# dbb_ctrl register map
Registers are 16-bit, access not given, no defined reset value unless marked. A register's access mark holds for its fields unless they carry their own. Offsets are from the block's base; lines under a group give offsets from that group; [hi:lo] are bit positions; {n}, {i} and the like mark numbered series; 'fields as' and 'values as' point back to an identical list; <NAME> marks a mode.

## Memory map
? dbb_ctrl — DIBS Control Config

## dbb_ctrl — DIBS Control Config
Base ?
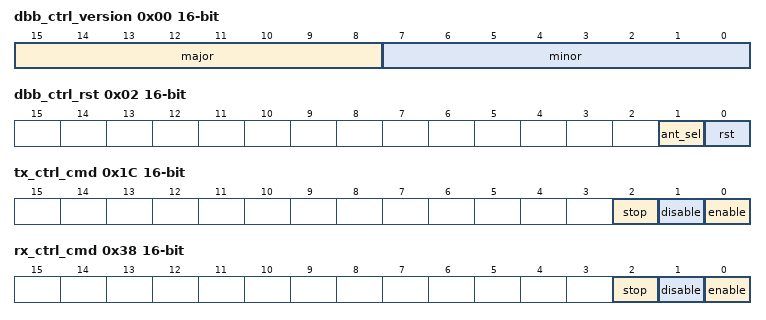
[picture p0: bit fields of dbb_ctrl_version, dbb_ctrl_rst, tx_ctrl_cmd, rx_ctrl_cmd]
0x00 dbb_ctrl_version — version
  [15:8] major — version register major
  [7:0] minor — Version register minor
0x02 dbb_ctrl_rst — Digital baseband reset
  [1] ant_sel
  [0] rst — reset
0x04 tx_ctrl_dbb_en_dly — When a transmit needs to start automatically after Tifs
{0x8+4i} tx_ctrl_rffe_en_dly[{i}] (i=0..1) — RFE enable dly [1]: the delay between the start of the SPI sequencer or the POWER on. RFE enable delay [2]: the delay between the start of the second burst and the POWER on. (if the RFE enable delay [2] = 0 there is no second burst)
0x10 tx_ctrl_dbb_dis_dly — the delay for disabling the DBB
{0x14+4i} tx_ctrl_rffe_dis_dly[{i}] (i=0..1) — RFE disable dly [1]: the delay between the start of the SPI sequencer or the POWER on. RFE disable delay [2]: the delay between the start of the second burst and the POWER on. (if the RFE disable delay [2] = 0 there is no second burst)
0x1C tx_ctrl_cmd — cmd
  [2] stop — Stops the automatic timing for TIFS
  [1] disable — Direct register control disable of TX transmission
  [0] enable — Direct register control enable of TX transmission
0x1E tx_ctrl_debug_en_tx_on_sfd_to — Besides RX received also enable TX on SFD timeout (used for debugging only)
0x20 rx_ctrl_dbb_en_dly — When a transmit needs to start automatically after Tifs
{0x24+4i} rx_ctrl_rffe_en_dly[{i}] (i=0..1) — RFE enable dly [1]: the delay between the start of the SPI sequencer or the POWER on. RFE enable delay [2]: the delay between the start of the second burst and the POWER on. (if the RFE enable delay [2] = 0 there is no second burst)
0x2C rx_ctrl_dbb_dis_dly — the delay for disabling the DBB
{0x30+4i} rx_ctrl_rffe_dis_dly[{i}] (i=0..1) — RFE disable dly [1]: the delay between the start of the SPI sequencer or the POWER on. RFE disable delay [2]: the delay between the start of the second burst and the POWER on. (if the RFE disable delay [2] = 0 there is no second burst)
0x38 rx_ctrl_cmd — cmd
  [2] stop — Stops the automatic timing for TIFS
  [1] disable — Direct register control disable of RX transmission
  [0] enable — Direct register control enable of RX transmission
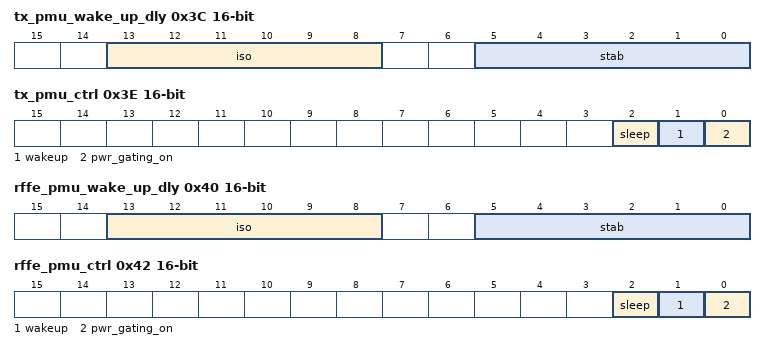
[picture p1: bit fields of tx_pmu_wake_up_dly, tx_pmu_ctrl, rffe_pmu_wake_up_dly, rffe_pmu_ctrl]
0x3C tx_pmu_wake_up_dly — wake_up_dly
  [13:8] iso — The delay between turning off the isolation and signalling that the power is on
  [5:0] stab — The delay between the wake up event and turning off the isolation
0x3E tx_pmu_ctrl — ctrl
  [2] sleep — Register controlled sleep
  [1] wakeup — Register controlled wakeup
  [0] pwr_gating_on — Actually do power gating, if off the power on signal is still toggled and is used to start the actual TX or RX
0x40 rffe_pmu_wake_up_dly — wake_up_dly
  fields as tx_pmu_wake_up_dly
0x42 rffe_pmu_ctrl — ctrl
  fields as tx_pmu_ctrl
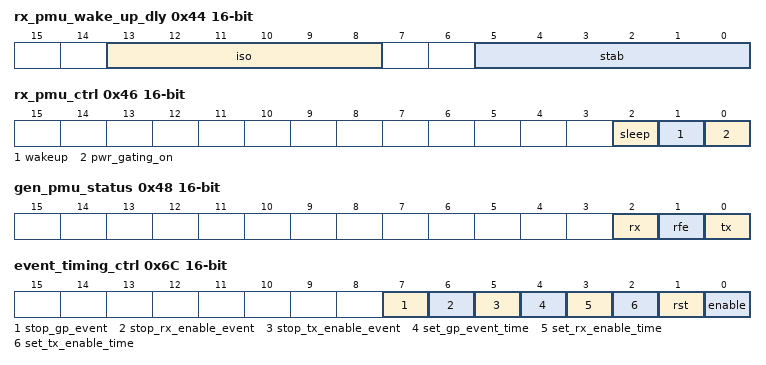
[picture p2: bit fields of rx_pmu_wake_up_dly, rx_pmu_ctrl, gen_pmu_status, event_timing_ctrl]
0x44 rx_pmu_wake_up_dly — wake_up_dly
  fields as tx_pmu_wake_up_dly
0x46 rx_pmu_ctrl — ctrl
  fields as tx_pmu_ctrl
0x48 gen_pmu_status — status
  [2] rx — Status shows if the power domain is not in the asleep mode
  [1] rfe — Status shows if the power domain is not in the asleep mode
  [0] tx — Status shows if the power domain is not in the asleep mode
0x4C event_timing_cntr_clk_mult_p — Counter clock rate multiplier multiplier value (the multiplier value can never be higher then the corresponding divider value)
0x4E event_timing_cntr_clk_div_q — Counter clock rate multiplier divider value
0x50 event_timing_cntr_val — Counter value (counter runs on clock determined by the counter clock rate multiplier)
0x54 event_timing_tx_enable_time — Time corresponding to the counter when the TX enable event should be given
0x58 event_timing_rx_enable_time — Time corresponding to the counter when the RX enable event should be given
0x5C event_timing_gp_event_time — Time corresponding to the counter when the general purpose event should be given
0x60 event_timing_tx_enable_delta_time — Time corresponding to the counter between two TX enable events starting from "tx_enable_time" (a value of 0 disables repetitive events, any other value enables them)
0x64 event_timing_rx_enable_delta_time — Time corresponding to the counter between two RX enable events starting from "rx_enable_time" (a value of 0 disables repetitive events, any other value enables them)
0x68 event_timing_gp_event_delta_time — Time corresponding to the counter between two general purpose events starting from "gp_event_time" (a value of 0 disables repetitive events, any other value enables them)
0x6C event_timing_ctrl — ctrl
  [7] stop_gp_event — Stop general purpose event (stops timed event)
  [6] stop_rx_enable_event — Stop RX enable event (stops timed event)
  [5] stop_tx_enable_event — Stop TX enable event (stops timed event)
  [4] set_gp_event_time — Set general purpose event time (enables timed event)
  [3] set_rx_enable_time — Set RX enable time (enables timed event)
  [2] set_tx_enable_time — Set TX enable time (enables timed event)
  [1] rst — Resets counter and event timing logic
  [0] enable — Counter, event timing and timestamping enable
0x70 event_timing_timestamp_tx_done — Event timestamp derived from the counter
0x74 event_timing_timestamp_rx_received — Event timestamp derived from the counter
0x78 event_timing_timestamp_rx_sfd_det — Event timestamp derived from the counter
0x7C event_timing_timestamp_rx_sfd_to — Event timestamp derived from the counter
0x80 event_timing_timestamp_rx_energy_det — Event timestamp derived from the counter
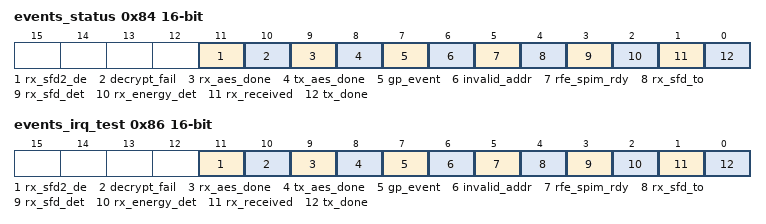
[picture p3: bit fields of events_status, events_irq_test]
0x84 events_status — status
  [11] rx_sfd2_de — debug purpose: read out if an event occurred.
  [10] decrypt_fail — debug purpose: read out if an event occurred.
  [9] rx_aes_done — debug purpose: read out if an event occurred.
  [8] tx_aes_done — debug purpose: read out if an event occurred.
  [7] gp_event — debug purpose: read out if an event occurred.
  [6] invalid_addr — debug purpose: read out if an event occurred.
  [5] rfe_spim_rdy — debug purpose: read out if an event occurred.
  [4] rx_sfd_to — debug purpose: read out if an event occurred.
  [3] rx_sfd_det — debug purpose: read out if an event occurred.
  [2] rx_energy_det — debug purpose: read out if an event occurred.
  [1] rx_received — debug purpose: read out if an event occurred.
  [0] tx_done — debug purpose: read out if an event occurred.
0x86 events_irq_test — irq_test
  [11] rx_sfd2_de — debug purpose: a pulse is generated to test the interrupt.
  [10] decrypt_fail — debug purpose: a pulse is generated to test the interrupt.
  [9] rx_aes_done — debug purpose: a pulse is generated to test the interrupt.
  [8] tx_aes_done — debug purpose: a pulse is generated to test the interrupt.
  [7] gp_event — debug purpose: a pulse is generated to test the interrupt
  [6] invalid_addr — debug purpose: a pulse is generated to test the interrupt
  [5] rfe_spim_rdy — debug purpose: a pulse is generated to test the interrupt
  [4] rx_sfd_to — debug purpose: a pulse is generated to test the interrupt
  [3] rx_sfd_det — debug purpose: a pulse is generated to test the interrupt
  [2] rx_energy_det — debug purpose: a pulse is generated to test the interrupt
  [1] rx_received — debug purpose: a pulse is generated to test the interrupt
  [0] tx_done — debug purpose: a pulse is generated to test the interrupt
0x88 cmu_gating_on — Clock gating on
0x8A cmu_main_mult_p — The rate multiplier multiplier value (the multiplier value can never be higher then the corresponding divider value)
0x8C cmu_main_div_q — The rate multiplier divider value
0x8E cmu_phy_mult_p — The rate multiplier multiplier value (the multiplier value can never be higher then the corresponding divider value)
0x90 cmu_phy_div_q — The rate multiplier divider value
0x92 cmu_dl_mult_p — The rate multiplier multiplier value (the multiplier value can never be higher then the corresponding divider value)
0x94 cmu_dl_div_q — The rate multiplier divider value
0x100 aes_st 32-bit — AES status.
0x104 aes_aad 32-bit — AES address.
0x10C aes_ctrl 32-bit — AES control.
{0x110+i} aes_key[{i}] (i=0..15) 8-bit
{0x120+i} aes_ctr_blk[{i}] (i=0..15) 8-bit — AES counter block.
